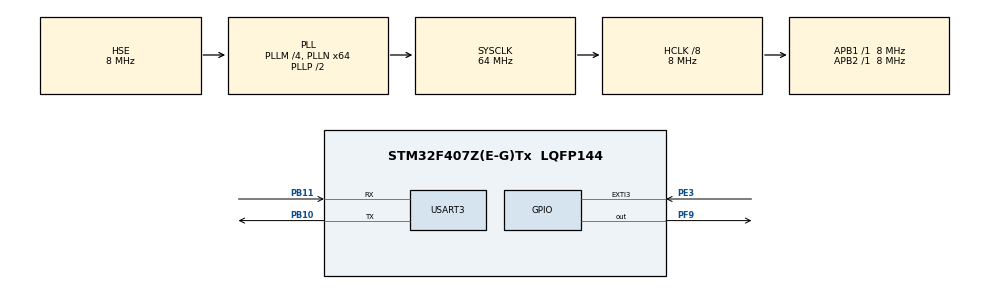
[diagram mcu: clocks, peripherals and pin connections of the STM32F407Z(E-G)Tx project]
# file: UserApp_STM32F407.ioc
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Mcu.Family=STM32F4
Mcu.Name=STM32F407Z(E-G)Tx
Mcu.Package=LQFP144
NVIC.EXTI3_IRQn=true\:0\:0\:false\:false\:true\:true\:true\:true
NVIC.PriorityGroup=NVIC_PRIORITYGROUP_4
PB10.Mode=Asynchronous
PB10.Signal=USART3_TX
PB11.Mode=Asynchronous
PB11.Signal=USART3_RX
PE3.GPIO_ModeDefaultEXTI=GPIO_MODE_IT_FALLING
PE3.GPIO_PuPd=GPIO_PULLUP
PE3.Signal=GPXTI3
PF9.PinState=GPIO_PIN_SET
PF9.Signal=GPIO_Output
PH0-OSC_IN.Mode=HSE-External-Oscillator
PH0-OSC_IN.Signal=RCC_OSC_IN
PH1-OSC_OUT.Mode=HSE-External-Oscillator
PH1-OSC_OUT.Signal=RCC_OSC_OUT
ProjectManager.HeapSize=0x200
ProjectManager.StackSize=0x400
ProjectManager.TargetToolchain=STM32CubeIDE
RCC.48MHZClocksFreq_Value=32000000
RCC.AHBCLKDivider=RCC_SYSCLK_DIV8
RCC.AHBFreq_Value=8000000
RCC.APB1Freq_Value=8000000
RCC.APB1TimFreq_Value=8000000
RCC.APB2Freq_Value=8000000
RCC.APB2TimFreq_Value=8000000
RCC.CortexFreq_Value=8000000
RCC.HCLKFreq_Value=8000000
RCC.HSE_VALUE=8000000
RCC.HSI_VALUE=16000000
RCC.LSE_VALUE=32768
RCC.PLLM=4
RCC.PLLN=64
RCC.PLLSourceVirtual=RCC_PLLSOURCE_HSE
RCC.SYSCLKFreq_VALUE=64000000
RCC.SYSCLKSource=RCC_SYSCLKSOURCE_PLLCLK
RCC.VCOOutputFreq_Value=128000000
USART3.VirtualMode=VM_ASYNC
board=custom

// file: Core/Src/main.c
/* USER CODE BEGIN Header */
/**
  ******************************************************************************
  * @file           : main.c
  * @brief          : Main program body
  ******************************************************************************
  * @attention
  *
  * Copyright (c) 2024 STMicroelectronics.
  * All rights reserved.
  *
  * This software is licensed under terms that can be found in the LICENSE file
  * in the root directory of this software component.
  * If no LICENSE file comes with this software, it is provided AS-IS.
  *
  ******************************************************************************
  */
/* USER CODE END Header */
#include "main.h"

UART_HandleTypeDef huart3;

/* USER CODE BEGIN PV */
char user_data[] = "User Application\r\n";
/* USER CODE END PV */

void SystemClock_Config(void);
static void MX_GPIO_Init(void);
static void MX_USART3_UART_Init(void);

int main(void)
{

  /* MCU Configuration--------------------------------------------------------*/

  /* Reset of all peripherals, Initializes the Flash interface and the Systick. */
  HAL_Init();

  /* Configure the system clock */
  SystemClock_Config();

  /* Initialize all configured peripherals */
  MX_GPIO_Init();
  MX_USART3_UART_Init();

  /* Infinite loop */
  while (1)
  {

    /* USER CODE BEGIN 3 */
	HAL_UART_Transmit(&huart3, (uint8_t *)user_data, sizeof(user_data), HAL_MAX_DELAY);
	HAL_Delay(1000);
  }
  /* USER CODE END 3 */
}

void SystemClock_Config(void)
{
  RCC_OscInitTypeDef RCC_OscInitStruct = {0};
  RCC_ClkInitTypeDef RCC_ClkInitStruct = {0};

  /** Configure the main internal regulator output voltage
  */
  __HAL_RCC_PWR_CLK_ENABLE();
  __HAL_PWR_VOLTAGESCALING_CONFIG(PWR_REGULATOR_VOLTAGE_SCALE1);

  /** Initializes the RCC Oscillators according to the specified parameters
  * in the RCC_OscInitTypeDef structure.
  */
  RCC_OscInitStruct.OscillatorType = RCC_OSCILLATORTYPE_HSE;
  RCC_OscInitStruct.HSEState = RCC_HSE_ON;
  RCC_OscInitStruct.PLL.PLLState = RCC_PLL_ON;
  RCC_OscInitStruct.PLL.PLLSource = RCC_PLLSOURCE_HSE;
  RCC_OscInitStruct.PLL.PLLM = 4;
  RCC_OscInitStruct.PLL.PLLN = 64;
  RCC_OscInitStruct.PLL.PLLP = RCC_PLLP_DIV2;
  RCC_OscInitStruct.PLL.PLLQ = 4;
  if (HAL_RCC_OscConfig(&RCC_OscInitStruct) != HAL_OK)
  {
    Error_Handler();
  }

  /** Initializes the CPU, AHB and APB buses clocks
  */
  RCC_ClkInitStruct.ClockType = RCC_CLOCKTYPE_HCLK|RCC_CLOCKTYPE_SYSCLK
                              |RCC_CLOCKTYPE_PCLK1|RCC_CLOCKTYPE_PCLK2;
  RCC_ClkInitStruct.SYSCLKSource = RCC_SYSCLKSOURCE_PLLCLK;
  RCC_ClkInitStruct.AHBCLKDivider = RCC_SYSCLK_DIV8;
  RCC_ClkInitStruct.APB1CLKDivider = RCC_HCLK_DIV1;
  RCC_ClkInitStruct.APB2CLKDivider = RCC_HCLK_DIV1;

  if (HAL_RCC_ClockConfig(&RCC_ClkInitStruct, FLASH_LATENCY_0) != HAL_OK)
  {
    Error_Handler();
  }
}

static void MX_USART3_UART_Init(void)
{

  huart3.Instance = USART3;
  huart3.Init.BaudRate = 115200;
  huart3.Init.WordLength = UART_WORDLENGTH_8B;
  huart3.Init.StopBits = UART_STOPBITS_1;
  huart3.Init.Parity = UART_PARITY_NONE;
  huart3.Init.Mode = UART_MODE_TX_RX;
  huart3.Init.HwFlowCtl = UART_HWCONTROL_NONE;
  huart3.Init.OverSampling = UART_OVERSAMPLING_16;
  if (HAL_UART_Init(&huart3) != HAL_OK)
  {
    Error_Handler();
  }

}

static void MX_GPIO_Init(void)
{
  GPIO_InitTypeDef GPIO_InitStruct = {0};

  /* GPIO Ports Clock Enable */
  __HAL_RCC_GPIOE_CLK_ENABLE();
  __HAL_RCC_GPIOF_CLK_ENABLE();
  __HAL_RCC_GPIOH_CLK_ENABLE();
  __HAL_RCC_GPIOB_CLK_ENABLE();

  /*Configure GPIO pin Output Level */
  HAL_GPIO_WritePin(GPIOF, GPIO_PIN_9, GPIO_PIN_SET);

  /*Configure GPIO pin : PE3 */
  GPIO_InitStruct.Pin = GPIO_PIN_3;
  GPIO_InitStruct.Mode = GPIO_MODE_IT_FALLING;
  GPIO_InitStruct.Pull = GPIO_PULLUP;
  HAL_GPIO_Init(GPIOE, &GPIO_InitStruct);

  /*Configure GPIO pin : PF9 */
  GPIO_InitStruct.Pin = GPIO_PIN_9;
  GPIO_InitStruct.Mode = GPIO_MODE_OUTPUT_PP;
  GPIO_InitStruct.Pull = GPIO_NOPULL;
  GPIO_InitStruct.Speed = GPIO_SPEED_FREQ_LOW;
  HAL_GPIO_Init(GPIOF, &GPIO_InitStruct);

  /* EXTI interrupt init*/
  HAL_NVIC_SetPriority(EXTI3_IRQn, 0, 0);
  HAL_NVIC_EnableIRQ(EXTI3_IRQn);

}

void Error_Handler(void)
{
  __disable_irq();
  while (1)
  {
  }
}
